# daric register map
Vendor: cramium
Registers are 32-bit, read-write, reset 0x0 unless marked. A register's access mark holds for its fields unless they carry their own. Offsets are from the block's base; [hi:lo] are bit positions; {n}, {i} and the like mark numbered series.

## UDMA_SDIO
Base 0x5010D000
0x00 REG_RX_SADDR — See file:///F:/code/cram-soc/soc_oss/ips/udma/udma_sdio/rtl/udma_sdio_reg_if.sv
  [11:0] r_rx_startaddr
0x04 REG_RX_SIZE — See file:///F:/code/cram-soc/soc_oss/ips/udma/udma_sdio/rtl/udma_sdio_reg_if.sv
  [15:0] r_rx_size
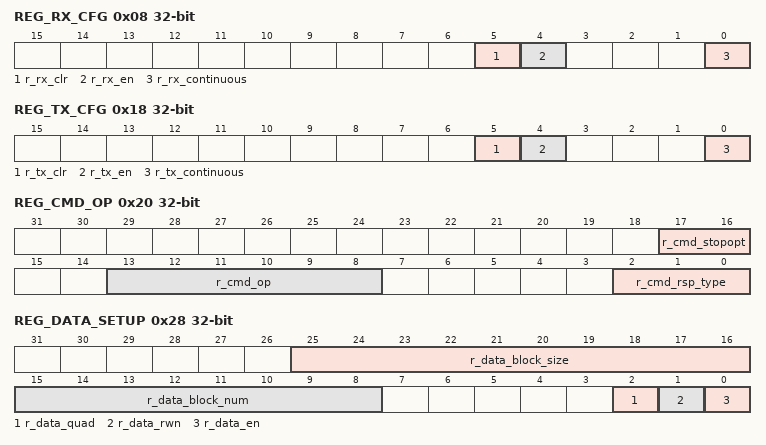
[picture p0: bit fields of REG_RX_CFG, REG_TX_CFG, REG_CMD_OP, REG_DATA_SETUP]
0x08 REG_RX_CFG — See file:///F:/code/cram-soc/soc_oss/ips/udma/udma_sdio/rtl/udma_sdio_reg_if.sv
  [5] r_rx_clr, [4] r_rx_en, [0] r_rx_continuous
0x10 REG_TX_SADDR — See file:///F:/code/cram-soc/soc_oss/ips/udma/udma_sdio/rtl/udma_sdio_reg_if.sv
  [11:0] r_tx_startaddr
0x14 REG_TX_SIZE — See file:///F:/code/cram-soc/soc_oss/ips/udma/udma_sdio/rtl/udma_sdio_reg_if.sv
  [15:0] r_tx_size
0x18 REG_TX_CFG — See file:///F:/code/cram-soc/soc_oss/ips/udma/udma_sdio/rtl/udma_sdio_reg_if.sv
  [5] r_tx_clr, [4] r_tx_en, [0] r_tx_continuous
0x20 REG_CMD_OP — See file:///F:/code/cram-soc/soc_oss/ips/udma/udma_sdio/rtl/udma_sdio_reg_if.sv
  [17:16] r_cmd_stopopt, [13:8] r_cmd_op, [2:0] r_cmd_rsp_type
0x28 REG_DATA_SETUP — See file:///F:/code/cram-soc/soc_oss/ips/udma/udma_sdio/rtl/udma_sdio_reg_if.sv
  [25:16] r_data_block_size, [15:8] r_data_block_num, [2] r_data_quad, [1] r_data_rwn, [0] r_data_en
0x2C REG_START — See file:///F:/code/cram-soc/soc_oss/ips/udma/udma_sdio/rtl/udma_sdio_reg_if.sv
  [0] r_sdio_start
{0x30+4i} REG_RSP{i} (i=0..3) — See file:///F:/code/cram-soc/soc_oss/ips/udma/udma_sdio/rtl/udma_sdio_reg_if.sv
  [31:0] cfg_rsp_data_i_{32i+31}_{32i}
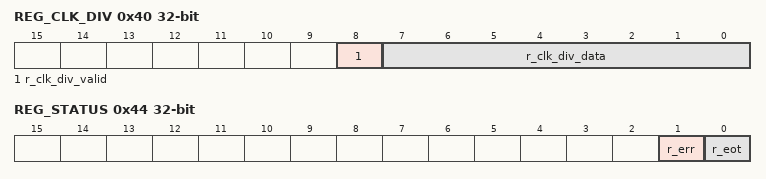
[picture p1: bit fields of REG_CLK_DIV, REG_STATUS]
0x40 REG_CLK_DIV — See file:///F:/code/cram-soc/soc_oss/ips/udma/udma_sdio/rtl/udma_sdio_reg_if.sv
  [8] r_clk_div_valid, [7:0] r_clk_div_data
0x44 REG_STATUS — See file:///F:/code/cram-soc/soc_oss/ips/udma/udma_sdio/rtl/udma_sdio_reg_if.sv
  [1] r_err, [0] r_eot

## UDMA_I2S
Base 0x5010E000
0x00 REG_RX_SADDR — See file:///F:/code/cram-soc/soc_oss/ips/udma/udma_i2s/rtl/udma_i2s_reg_if.sv
  [11:0] r_rx_startaddr
0x04 REG_RX_SIZE — See file:///F:/code/cram-soc/soc_oss/ips/udma/udma_i2s/rtl/udma_i2s_reg_if.sv
  [15:0] r_rx_size
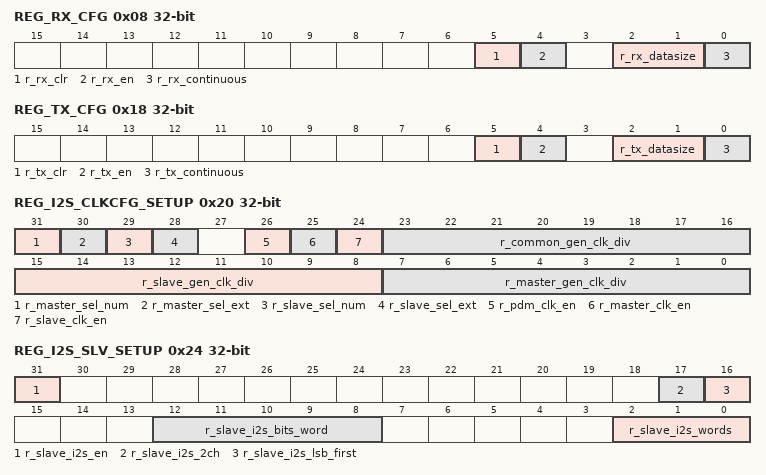
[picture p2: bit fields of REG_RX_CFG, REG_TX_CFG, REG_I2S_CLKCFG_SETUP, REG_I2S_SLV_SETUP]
0x08 REG_RX_CFG — See file:///F:/code/cram-soc/soc_oss/ips/udma/udma_i2s/rtl/udma_i2s_reg_if.sv
  [5] r_rx_clr, [4] r_rx_en, [2:1] r_rx_datasize, [0] r_rx_continuous
0x10 REG_TX_SADDR — See file:///F:/code/cram-soc/soc_oss/ips/udma/udma_i2s/rtl/udma_i2s_reg_if.sv
  [11:0] r_tx_startaddr
0x14 REG_TX_SIZE — See file:///F:/code/cram-soc/soc_oss/ips/udma/udma_i2s/rtl/udma_i2s_reg_if.sv
  [15:0] r_tx_size
0x18 REG_TX_CFG — See file:///F:/code/cram-soc/soc_oss/ips/udma/udma_i2s/rtl/udma_i2s_reg_if.sv
  [5] r_tx_clr, [4] r_tx_en, [2:1] r_tx_datasize, [0] r_tx_continuous
0x20 REG_I2S_CLKCFG_SETUP — See file:///F:/code/cram-soc/soc_oss/ips/udma/udma_i2s/rtl/udma_i2s_reg_if.sv
  [31] r_master_sel_num, [30] r_master_sel_ext, [29] r_slave_sel_num, [28] r_slave_sel_ext, [26] r_pdm_clk_en, [25] r_master_clk_en, [24] r_slave_clk_en, [23:16] r_common_gen_clk_div, [15:8] r_slave_gen_clk_div, [7:0] r_master_gen_clk_div
0x24 REG_I2S_SLV_SETUP — See file:///F:/code/cram-soc/soc_oss/ips/udma/udma_i2s/rtl/udma_i2s_reg_if.sv
  [31] r_slave_i2s_en, [17] r_slave_i2s_2ch, [16] r_slave_i2s_lsb_first, [12:8] r_slave_i2s_bits_word, [2:0] r_slave_i2s_words
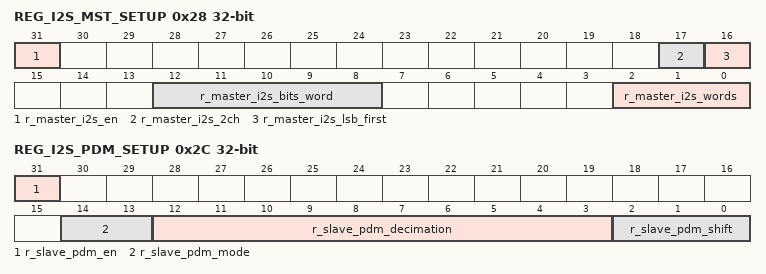
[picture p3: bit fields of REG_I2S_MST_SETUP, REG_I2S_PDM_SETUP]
0x28 REG_I2S_MST_SETUP — See file:///F:/code/cram-soc/soc_oss/ips/udma/udma_i2s/rtl/udma_i2s_reg_if.sv
  [31] r_master_i2s_en, [17] r_master_i2s_2ch, [16] r_master_i2s_lsb_first, [12:8] r_master_i2s_bits_word, [2:0] r_master_i2s_words
0x2C REG_I2S_PDM_SETUP — See file:///F:/code/cram-soc/soc_oss/ips/udma/udma_i2s/rtl/udma_i2s_reg_if.sv
  [31] r_slave_pdm_en, [14:13] r_slave_pdm_mode, [12:3] r_slave_pdm_decimation, [2:0] r_slave_pdm_shift

## UDMA_CAMERA
Base 0x5010F000
0x00 REG_RX_SADDR — See file:///F:/code/cram-soc/soc_oss/ips/udma/udma_camera/rtl/camera_reg_if.sv
  [11:0] r_rx_startaddr
0x04 REG_RX_SIZE — See file:///F:/code/cram-soc/soc_oss/ips/udma/udma_camera/rtl/camera_reg_if.sv
  [15:0] r_rx_size
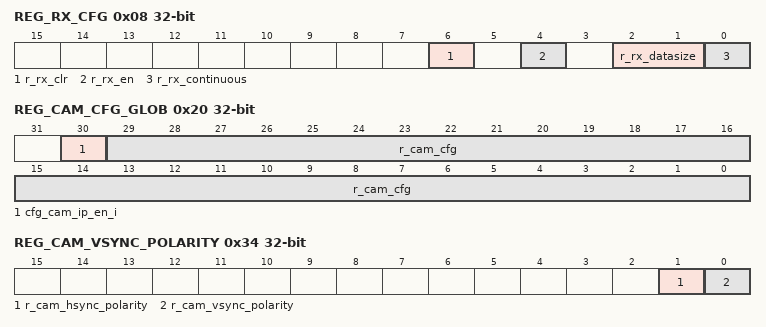
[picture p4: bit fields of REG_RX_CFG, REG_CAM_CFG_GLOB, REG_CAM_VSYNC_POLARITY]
0x08 REG_RX_CFG — See file:///F:/code/cram-soc/soc_oss/ips/udma/udma_camera/rtl/camera_reg_if.sv
  [6] r_rx_clr, [4] r_rx_en, [2:1] r_rx_datasize, [0] r_rx_continuous
0x20 REG_CAM_CFG_GLOB — See file:///F:/code/cram-soc/soc_oss/ips/udma/udma_camera/rtl/camera_reg_if.sv
  [30] cfg_cam_ip_en_i, [29:0] r_cam_cfg
0x24 REG_CAM_CFG_LL — See file:///F:/code/cram-soc/soc_oss/ips/udma/udma_camera/rtl/camera_reg_if.sv
  [31:0] r_cam_cfg_ll
0x28 REG_CAM_CFG_UR — See file:///F:/code/cram-soc/soc_oss/ips/udma/udma_camera/rtl/camera_reg_if.sv
  [31:0] r_cam_cfg_ur
0x2C REG_CAM_CFG_SIZE — See file:///F:/code/cram-soc/soc_oss/ips/udma/udma_camera/rtl/camera_reg_if.sv
  [31:0] r_cam_cfg_size
0x30 REG_CAM_CFG_FILTER — See file:///F:/code/cram-soc/soc_oss/ips/udma/udma_camera/rtl/camera_reg_if.sv
  [31:0] r_cam_cfg_filter
0x34 REG_CAM_VSYNC_POLARITY — See file:///F:/code/cram-soc/soc_oss/ips/udma/udma_camera/rtl/camera_reg_if.sv
  [1] r_cam_hsync_polarity, [0] r_cam_vsync_polarity
